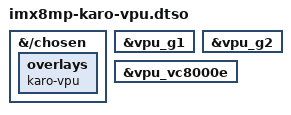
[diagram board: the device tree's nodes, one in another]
// SPDX-License-Identifier: (GPL-2.0 OR BSD-3-Clause)
/*
 * Copyright (C) 2022 Lothar Waßmann <LW@KARO-electronics.de>
 */

/dts-v1/;

/plugin/;

&{/chosen} {
	overlays {
		karo-vpu;
	};
};

&vpu_g1 {
	status = "okay";
};

&vpu_g2 {
	status = "okay";
};

&vpu_vc8000e {
	status = "okay";
};
